# STM32H503 register map
File version: 1.5
CPU: CM33 r0p0, little endian, MPU, FPU, 4 interrupt priority bits
Registers are 32-bit, read-write, reset 0x0 unless marked. A register's access mark holds for its fields unless they carry their own. Offsets are from the block's base; [hi:lo] are bit positions; {n}, {i} and the like mark numbered series.

## PWR — Power control
Base 0x44020800
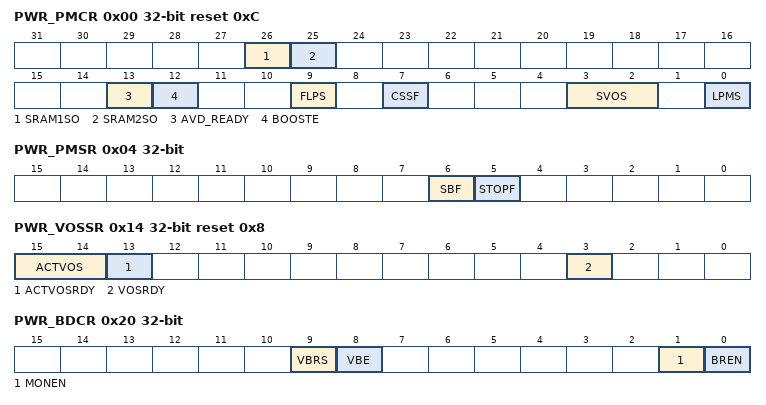
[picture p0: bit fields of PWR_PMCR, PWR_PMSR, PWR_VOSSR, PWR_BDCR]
0x00 PWR_PMCR reset 0xC — PWR power mode control register
  [26] SRAM1SO — AHB SRAM1 shut-off in Stop mode
    0=AHB RAM1 content is kept in Stop mode; 1=AHB RAM1 content is lost in Stop mode
  [25] SRAM2SO — AHB SRAM2 shut-off in Stop mode.
    0=AHB RAM2 content is kept in Stop mode; 1=AHB RAM2 content is lost in Stop mode
  [13] AVD_READY — analog voltage ready This bit is only used when the analog switch boost needs to be enabled (see BOOSTE bit). It must be set by software when the expected V DDA analog supply level is available. The correct analog supply level is indicated by the AVDO bit (PWR_VMSR register) after setting the AVDEN bit (PWR_VMCR register) and selecting the supply level to be monitored (ALS bits).
    0=peripheral analog voltage V DDA not ready (default); 1=peripheral analog voltage V DDA ready
  [12] BOOSTE — analog switch V BOOST control This bit enables the booster to guarantee the analog switch AC performance when the V DD supply voltage is below 2.7 V (reduction of the total harmonic distortion to have the same switch performance over the full supply voltage range) The V DD supply voltage can be monitored through the PVD and the PLS bits.
    0=booster disabled (default); 1=booster enabled if analog voltage ready (AVD_READY = 1)
  [9] FLPS — Flash memory low-power mode in Stop mode This bit is used to obtain the best trade-off between low-power consumption and restart time when exiting from Stop mode. When it is set, the Flash memory enters low-power mode when the CPU domain is in Stop mode. Note: When system enters stop mode with SVOS5 enabled, Flash memory is automatically forced in low-power mode.
    0=Flash memory remains in normal mode when the CPU domain enters Stop mode (quick restart time); 1=Flash memory enters low-power mode when the CPU domain enters Stop mode (low power consumption)
  [7] CSSF — clear Standby and Stop flags (always read as 0) This bit is cleared to 0 by hardware.
    0=no effect; 1=STOPF and SBF flags cleared
  [3:2] SVOS — system Stop mode voltage scaling selection These bits control the V CORE voltage level in system Stop mode, to obtain the best trade-off between power consumption and performance.
    1=SVOS5 scale 5; 2=SVOS4 scale 4; 3=SVOS3 scale 3 (default)
  [0] LPMS — low-power mode selection This bit defines the Deepsleep mode.
    0=Keeps Stop mode when entering DeepSleep; 1=Allows Standby mode when entering DeepSleep
0x04 PWR_PMSR ro — PWR status register
  [6] SBF — System standby flag This bit is set by hardware and cleared only by a POR or by setting the CSSF bit.
    0=system has not been in Standby mode; 1=system has been in Standby mode
  [5] STOPF — Stop flag This bit is set by hardware and cleared only by any reset or by setting the CSSF bit.
    0=system has not been in Stop mode; 1=system has been in Stop mode
0x10 PWR_VOSCR — PWR voltage scaling control register
  [5:4] VOS — voltage scaling selection according to performance These bits control the V CORE voltage level and allow to obtain the best trade-off between power consumption and performance: - In bypass mode, these bits must also be set according to the external provided core voltage level and related performance. - When increasing the performance, the voltage scaling must be changed before increasing the system frequency. - When decreasing performance, the system frequency must first be decreased before changing the voltage scaling.
    0=scale 3 (default); 1=scale 2; 2=scale 1; 3=scale 0
0x14 PWR_VOSSR ro reset 0x8 — PWR voltage scaling status register
  [15:14] ACTVOS — voltage output scaling currently applied to V CORE This field provides the last VOS value.
    0=VOS3 (lowest power); 1=VOS2; 2=VOS1; 3=VOS0 (highest frequency)
  [13] ACTVOSRDY — Voltage level ready for currently used VOS
    0=V CORE is above or below the current voltage scaling provided by ACTVOS[1:0]; 1=V CORE is equal to the current voltage scaling provided by ACTVOS[1:0]
  [3] VOSRDY — Ready bit for V CORE voltage scaling output selection.
    0=Not ready, voltage level below VOS selected level; 1=Ready, voltage level at or above VOS selected level
0x20 PWR_BDCR — PWR Backup domain control register
  [9] VBRS — V BAT charging resistor selection
    0=Charge V BAT through a 5 kohm resistor; 1=Charge V BAT through a 1.5 kohm resistor
  [8] VBE — V BAT charging enable Note: Reset only by POR,.
    0=V BAT battery charging disabled; 1=V BAT battery charging enabled
  [1] MONEN — Backup domain voltage and temperature monitoring enable
    0=Backup domain voltage and temperature monitoring disabled; 1=Backup domain voltage and temperature monitoring enabled
  [0] BREN — Backup RAM retention in Standby and V BAT modes When this bit set, the backup regulator (used to maintain the backup RAM content in Standby and V BAT modes) is enabled. If BREN is cleared, the backup regulator is switched off. The backup RAM can still be used in Run and Stop modes. However its content is lost in Standby and V BAT modes. If BREN is set, the application must wait till the backup regulator ready flag (BRRDY) is set to indicate that the data written into the SRAM is maintained in Standby and V BAT modes.
    0=Backup RAM content lost in Standby and V BAT modes; 1=Backup RAM content preserved in Standby and V BAT modes
0x24 PWR_DBPCR — PWR disable backup protection control register
  [0] DBP — Disable Backup domain write protection In reset state, all registers and SRAM in Backup domain are protected against parasitic write access. This bit must be set to enable write access to these registers.
    0=Write access to Backup domain disabled; 1=Write access to Backup domain enabled
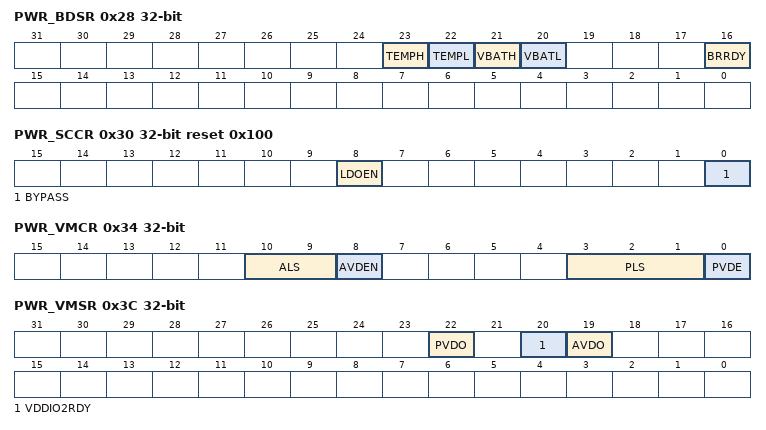
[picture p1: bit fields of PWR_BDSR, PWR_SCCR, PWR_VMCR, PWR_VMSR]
0x28 PWR_BDSR ro — PWR Backup domain status register
  [23] TEMPH — temperature level monitoring versus high threshold
    0=temperature below high threshold level; 1=temperature equal or above high threshold level
  [22] TEMPL — temperature level monitoring versus low threshold
    0=temperature above low threshold level; 1=temperature equal or below low threshold level
  [21] VBATH — V BAT level monitoring versus high threshold
    0=V BAT level below high threshold level; 1=V BAT level equal or above high threshold level
  [20] VBATL — V BAT level monitoring versus low threshold
    0=V BAT level above low threshold level; 1=V BAT level equal or below low threshold level
  [16] BRRDY — backup regulator ready This bit is set by hardware to indicate that the backup regulator is ready.
    0=backup regulator not ready; 1=backup regulator ready
0x30 PWR_SCCR access per field reset 0x100 — PWR supply configuration control register
  [8] LDOEN ro — LDO enable The value is set by hardware when the package uses the LDO regulator.
  [0] BYPASS rw-once — power management unit bypass
    0=Power management unit normal operation. Use the internal regulator.; 1=Power management unit bypassed. Use the external power (voltage monitoring still active)
0x34 PWR_VMCR — PWR voltage monitor control register
  [10:9] ALS — analog voltage detector (AVD) level selection These bits select the voltage threshold detected by the AVD.
    0=1.7 V; 1=2.1 V; 2=2.5 V; 3=2.8 V
  [8] AVDEN — peripheral voltage monitor on V DDA enable
    0=peripheral voltage monitor on V DDA disabled; 1=peripheral voltage monitor on V DDA enabled
  [3:1] PLS — programmable voltage detector (PVD) level selection These bits select the voltage threshold detected by the PVD.
    0=1.95 V; 1=2.1 V; 2=2.25 V; 3=2.4 V; 4=2.55 V; 5=2.7 V; 6=2.85 V; 7=PVD_IN pin
  [0] PVDE — PVD enable
    0=PVD disabled; 1=PVD enabled
0x3C PWR_VMSR ro — PWR voltage monitor status register
  [22] PVDO — programmable voltage detect output This bit is set and cleared by hardware. It is valid only if the PVD has been enabled by the PVDE bit. Note: Since the PVD is disabled in Standby mode, this bit is equal to 0 after Standby or reset until the PVDE bit is set.
    0=V DD is equal or higher than the PVD threshold selected through the PLS[2:0] bits; 1=V DD is lower than the PVD threshold selected through the PLS[2:0] bits
  [20] VDDIO2RDY — voltage detector output on V DDIO2 This bit is set and cleared by hardware.
    0=V DDIO2 is below 1.2 V; 1=V DDIO2 is above or equal to 1.2 V
  [19] AVDO — analog voltage detector output on V DDA This bit is set and cleared by hardware. It is valid only if AVD on VDDA is enabled by the AVDEN bit. Note: Since the AVD is disabled in Standby mode, this bit is equal to 0 after standby or reset until the AVDEN bit is set.
    0=V DDA is equal or higher than the AVD threshold selected with the ALS[2:0] bits; 1=V DDA is lower than the AVD threshold selected with the ALS[2:0] bits
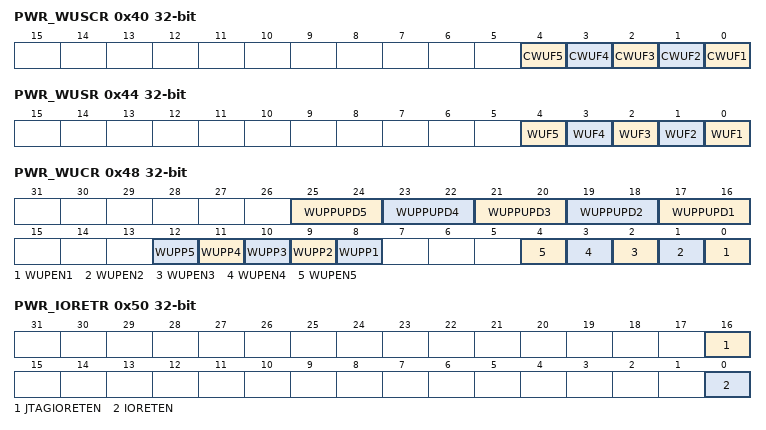
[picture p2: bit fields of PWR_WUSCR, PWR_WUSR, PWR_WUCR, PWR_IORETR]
0x40 PWR_WUSCR wo — PWR wakeup status clear register
  [all] fields
    0=no effect; 1=writing 1 clears the WUFx wakeup pin flag (bit is cleared to 0 by hardware)
  [n-1] CWUF{n} (n=1..5) — clear wakeup pin flag for WUFx These bits are always read as 0.
0x44 PWR_WUSR ro — PWR wakeup status register
  [all] fields
    0=no wakeup event occurred; 1=a wakeup event received from WUFx pin
  [n-1] WUF{n} (n=1..5) — wakeup pin WUFx flag This bit is set by hardware and cleared only by a RESET pin or by setting the CWUFx bit in PWR_WUSCR register.
0x48 PWR_WUCR — PWR wakeup configuration register
  [2n+15:2n+14] WUPPUPD{n} (n=1..5) — wakeup pin pull configuration for WKUPx These bits define the I/O pad pull configuration used when WUPENx = 1. The associated GPIO port pull configuration must be set to the same value or to 00. The wakeup pin pull configuration is kept in Standby mode.
    0=no pull-up; 1=pull-up; 2=pull-down
  [n+7] WUPP{n} (n=1..5) — wakeup pin polarity bit for WUPx These bits define the polarity used for event detection on WUPx external wakeup pin.
    0=detection on high level (rising edge); 1=detection on low level (falling edge)
  [n-1] WUPEN{n} (n=1..5) — enable wakeup pin WUPx These bits are set and cleared by software. Note: an additional wakeup event is detected if WUPx pin is enabled (by setting the WUPENx bit) when WUPx pin level is already high when WUPPx selects rising edge, or low when WUPPx selects falling edge.
    0=an event on WUPx pin does not wakeup the system from Standby mode; 1=a rising or falling edge on WUPx pin wakes up the system from Standby mode
0x50 PWR_IORETR — PWR I/O retention register
  [16] JTAGIORETEN — IO retention enable for JTAG IOs when entering into standby mode, the output is sampled, and applied to the output IO during the standby power mode
    0=IO Retention mode is disabled; 1=IO Retention mode is enabled for PA13, PA14, PA15 and PB4
  [0] IORETEN — IO retention enable: When entering into standby mode, the output is sampled, and applied to the output IO during the standby power mode. Note: the IO state is not retained if the DBG_STANDBY bit is set in DBGMCU_CR register.
    0=IO Retention mode is disabled; 1=IO Retention mode is enabled for all IOs except the ones supporting the standby functionality (PC13, PC14 and PC15) and JTAG I/Os (PA13, PA14, PA15, PB4)
0x104 PWR_PRIVCFGR — PWR privilege configuration register
  [1] NSPRIV — PWR functions privilege configuration Set and reset by software. This bit can be written only by privileged access.
    0=Read and write to PWR functions can be done by privileged or unprivileged access; 1=Read and write to PWR functions can be done by privileged access only
